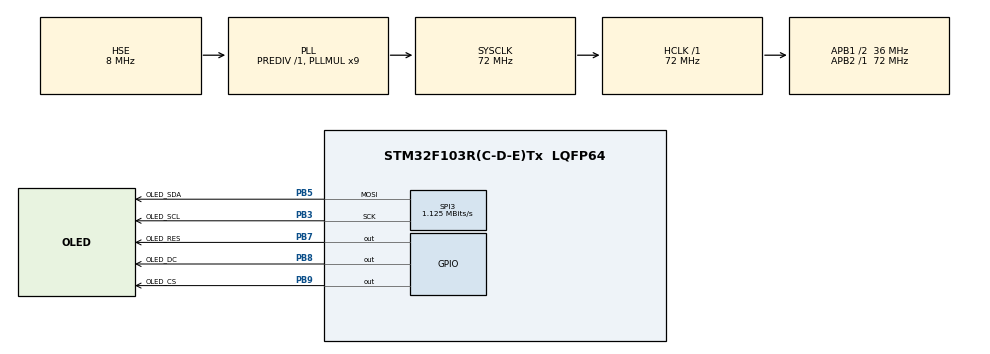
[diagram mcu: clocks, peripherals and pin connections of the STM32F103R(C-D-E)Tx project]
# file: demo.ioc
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Mcu.Family=STM32F1
Mcu.Name=STM32F103R(C-D-E)Tx
Mcu.Package=LQFP64
NVIC.PriorityGroup=NVIC_PRIORITYGROUP_4
PA13.Mode=Serial_Wire
PA13.Signal=SYS_JTMS-SWDIO
PA14.Mode=Serial_Wire
PA14.Signal=SYS_JTCK-SWCLK
PB3.GPIO_Label=OLED_SCL
PB3.Mode=TX_Only_Simplex_Unidirect_Master
PB3.Signal=SPI3_SCK
PB5.GPIO_Label=OLED_SDA
PB5.Mode=TX_Only_Simplex_Unidirect_Master
PB5.Signal=SPI3_MOSI
PB7.GPIO_Label=OLED_RES
PB7.Signal=GPIO_Output
PB8.GPIO_Label=OLED_DC
PB8.Signal=GPIO_Output
PB9.GPIO_Label=OLED_CS
PB9.GPIO_PuPd=GPIO_PULLUP
PB9.PinState=GPIO_PIN_SET
PB9.Signal=GPIO_Output
PD0-OSC_IN.Mode=HSE-External-Oscillator
PD0-OSC_IN.Signal=RCC_OSC_IN
PD1-OSC_OUT.Mode=HSE-External-Oscillator
PD1-OSC_OUT.Signal=RCC_OSC_OUT
ProjectManager.HeapSize=0x200
ProjectManager.StackSize=0x400
ProjectManager.TargetToolchain=MDK-ARM V5
RCC.AHBFreq_Value=72000000
RCC.APB1CLKDivider=RCC_HCLK_DIV2
RCC.APB1Freq_Value=36000000
RCC.APB1TimFreq_Value=72000000
RCC.APB2Freq_Value=72000000
RCC.APB2TimFreq_Value=72000000
RCC.HCLKFreq_Value=72000000
RCC.PLLMUL=RCC_PLL_MUL9
RCC.PLLSourceVirtual=RCC_PLLSOURCE_HSE
RCC.SYSCLKFreq_VALUE=72000000
RCC.SYSCLKSource=RCC_SYSCLKSOURCE_PLLCLK
RCC.USBFreq_Value=72000000
SPI3.BaudRatePrescaler=SPI_BAUDRATEPRESCALER_32
SPI3.CLKPhase=SPI_PHASE_2EDGE
SPI3.CLKPolarity=SPI_POLARITY_HIGH
SPI3.CalculateBaudRate=1.125 MBits/s
SPI3.Direction=SPI_DIRECTION_2LINES
SPI3.Mode=SPI_MODE_MASTER
SPI3.VirtualType=VM_MASTER
board=custom

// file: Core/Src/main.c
/* USER CODE BEGIN Header */
/**
 ******************************************************************************
 * @file           : main.c
 * @brief          : Main program body
 ******************************************************************************
 * @attention
 *
 * <h2><center>&copy; Copyright (c) 2022 STMicroelectronics.
 * All rights reserved.</center></h2>
 *
 * This software component is licensed by ST under BSD 3-Clause license,
 * the "License"; You may not use this file except in compliance with the
 * License. You may obtain a copy of the License at:
 *                        opensource.org/licenses/BSD-3-Clause
 *
 ******************************************************************************
 */
/* USER CODE END Header */

#include "main.h"
#include "gpio.h"
#include "spi.h"

/* USER CODE BEGIN Includes */
#include "SSD1306/ssd1306_spi.h"
/* USER CODE END Includes */

void SystemClock_Config(void);

int main(void) {

    /* MCU Configuration--------------------------------------------------------*/

    /* Reset of all peripherals, Initializes the Flash interface and the Systick. */
    HAL_Init();

    /* Configure the system clock */
    SystemClock_Config();

    /* Initialize all configured peripherals */
    MX_GPIO_Init();
    MX_SPI3_Init();

    /* Infinite loop */
    /* USER CODE BEGIN WHILE */

    // uint8_t t = ' ';
    // OLED_Init();
    LCD_Init();
    LCD_Print(0, 0, "搜索卫星...", TYPE16X16, TYPE8X16);
    LCD_Print(0, 16, "abcd09876", TYPE16X16, TYPE8X16);
    LCD_Print(16, 32, "efg12345", TYPE16X16, TYPE6X8);
    // OLED_Clear();
    while (1) {
        // Draw_BMP(32, 48, nonside);

        // Draw_BMP(48, 48, nonside);
        // Draw_BMP(64, 48, nonside);
        // OLED_Clear();
        // OLED_ShowChinese(0, 0, 0);    //中
        // OLED_ShowChinese(18, 0, 1);   //景
        // OLED_ShowChinese(36, 0, 2);   //园
        // OLED_ShowChinese(54, 0, 3);   //电
        // OLED_ShowChinese(72, 0, 4);   //子
        // OLED_ShowChinese(90, 0, 5);   //科
        // OLED_ShowChinese(108, 0, 6);  //技
        // OLED_ShowString(0, 3, "1.3' OLED TEST");
        // // OLED_ShowString(8,2,"ZHONGJINGYUAN");
        // //	OLED_ShowString(20,4,"2014/05/01");
        // OLED_ShowString(0, 6, "ASCII:");
        // OLED_ShowString(63, 6, "CODE:");
        // OLED_ShowChar(48, 6, t);  //显示ASCII字符
        // t++;
        // if (t > '~') t = ' ';
        // OLED_ShowNum(103, 6, t, 3, 16);  //显示ASCII字符的码值

        // delay_ms(8000);
        // OLED_Clear();
        // delay_ms(8000);
        // OLED_DrawBMP(0,0,128,8,BMP1);  //图片显示(图片显示慎用，生成的字表较大，会占用较多空间，FLASH空间8K以下慎用)
        // delay_ms(8000);
        // OLED_DrawBMP(0,0,128,8,BMP2);
        // delay_ms(8000);

        /* USER CODE END WHILE */

    }
}

void SystemClock_Config(void) {
    RCC_OscInitTypeDef RCC_OscInitStruct = {0};
    RCC_ClkInitTypeDef RCC_ClkInitStruct = {0};

    /** Initializes the CPU, AHB and APB busses clocks
     */
    RCC_OscInitStruct.OscillatorType = RCC_OSCILLATORTYPE_HSE;
    RCC_OscInitStruct.HSEState       = RCC_HSE_ON;
    RCC_OscInitStruct.HSEPredivValue = RCC_HSE_PREDIV_DIV1;
    RCC_OscInitStruct.HSIState       = RCC_HSI_ON;
    RCC_OscInitStruct.PLL.PLLState   = RCC_PLL_ON;
    RCC_OscInitStruct.PLL.PLLSource  = RCC_PLLSOURCE_HSE;
    RCC_OscInitStruct.PLL.PLLMUL     = RCC_PLL_MUL9;
    if (HAL_RCC_OscConfig(&RCC_OscInitStruct) != HAL_OK) {
        Error_Handler();
    }
    /** Initializes the CPU, AHB and APB busses clocks
     */
    RCC_ClkInitStruct.ClockType      = RCC_CLOCKTYPE_HCLK | RCC_CLOCKTYPE_SYSCLK | RCC_CLOCKTYPE_PCLK1 | RCC_CLOCKTYPE_PCLK2;
    RCC_ClkInitStruct.SYSCLKSource   = RCC_SYSCLKSOURCE_PLLCLK;
    RCC_ClkInitStruct.AHBCLKDivider  = RCC_SYSCLK_DIV1;
    RCC_ClkInitStruct.APB1CLKDivider = RCC_HCLK_DIV2;
    RCC_ClkInitStruct.APB2CLKDivider = RCC_HCLK_DIV1;

    if (HAL_RCC_ClockConfig(&RCC_ClkInitStruct, FLASH_LATENCY_2) != HAL_OK) {
        Error_Handler();
    }
}

void Error_Handler(void) {
}

/************************ (C) COPYRIGHT STMicroelectronics *****END OF FILE****/
